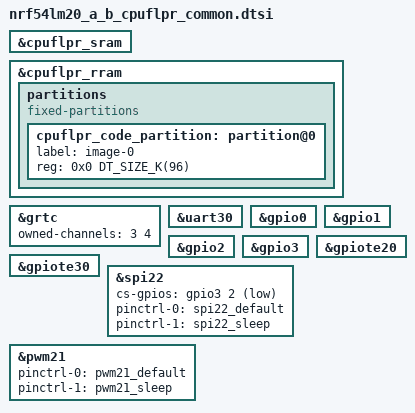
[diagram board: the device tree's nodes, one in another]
/*
 * Copyright (c) 2025 Nordic Semiconductor ASA
 *
 * SPDX-License-Identifier: Apache-2.0
 */

#include <nordic/nrf54lm20_a_b_cpuflpr.dtsi>
#include "nrf54lm20dk_common.dtsi"

&cpuflpr_sram {
	status = "okay";
};

&cpuflpr_rram {
	partitions {
		compatible = "fixed-partitions";
		#address-cells = <1>;
		#size-cells = <1>;
		ranges;

		cpuflpr_code_partition: partition@0 {
			label = "image-0";
			reg = <0x0 DT_SIZE_K(96)>;
		};
	};
};

&grtc {
	owned-channels = <3 4>;
	status = "okay";
};

&uart30 {
	status = "okay";
};

&gpio0 {
	status = "okay";
};

&gpio1 {
	status = "okay";
};

&gpio2 {
	status = "okay";
};

&gpio3 {
	status = "okay";
};

&gpiote20 {
	status = "okay";
};

&gpiote30 {
	status = "okay";
};

/*
 * Note this SPI instance conflicts with UART30. Disable or reconfigure pinctrl for UART30
 * to use this SPI instance.
 */
nordic_expansion_spi: &spi22 {
	cs-gpios = <&gpio3 2 GPIO_ACTIVE_LOW>;
	pinctrl-0 = <&spi22_default>;
	pinctrl-1 = <&spi22_sleep>;
	pinctrl-names = "default", "sleep";
};

nordic_expansion_pwm: &pwm21 {
	pinctrl-0 = <&pwm21_default>;
	pinctrl-1 = <&pwm21_sleep>;
	pinctrl-names = "default", "sleep";
};
